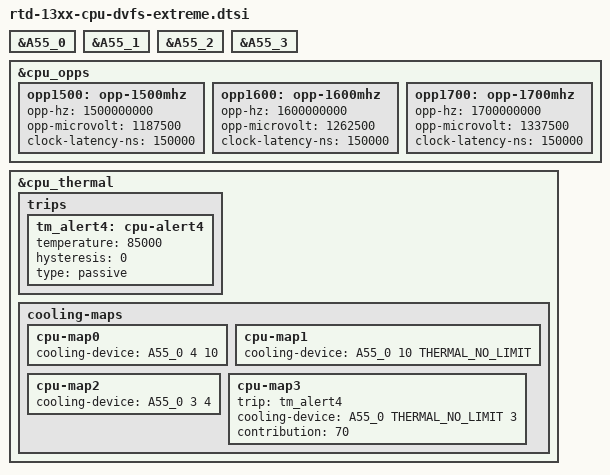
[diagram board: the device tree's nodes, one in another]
#include "rtd-13xx-cpu-dvfs.dtsi"

/*
 * Frequnecy overview
 *
 *    CDEV                             CDEV  CDEV  CDEV  CDEV
 *      ST  FREQUENCY   HLS   SUSPEND  MAP0  MAP1  MAP2  MAP3
 *       0       1700    V                                |
 *       1       1600    V                                |
 *       2       1500    V                                |
 *       3       1400    V                         -+-   -+-
 *       4       1300                  -+-         -+-
 *       5       1200            V      |
 *       6       1100                   |
 *       7       1000                   |
 *       8        900                   |
 *       9        800                  -+-
 *      10        700                        -+-
 *      11        600                         |
 *      12        500                         |
 *      13        400                         |
 *      14        300                         |
 */

&A55_0 {
};
&A55_1 {
};
&A55_2 {
};
&A55_3 {
};

&cpu_opps {
	opp1500: opp-1500mhz {
		opp-hz = /bits/ 64 <1500000000>;
		opp-microvolt = <1187500>;
		clock-latency-ns = <150000>;
		status = "okay";
	};
	opp1600: opp-1600mhz {
		opp-hz = /bits/ 64 <1600000000>;
		opp-microvolt = <1262500>;
		clock-latency-ns = <150000>;
		status = "okay";
	};
	opp1700: opp-1700mhz {
		opp-hz = /bits/ 64 <1700000000>;
		opp-microvolt = <1337500>;
		clock-latency-ns = <150000>;
		status = "okay";
	};
};
&cpu_thermal {
	trips {
		tm_alert4: cpu-alert4 {
			temperature = <85000>;
			hysteresis = <0>;
			type = "passive";
		};
	};
	cooling-maps {
		cpu-map0 {
			cooling-device = <&A55_0 4 10>;
		};
		cpu-map1 {
			cooling-device = <&A55_0 10 THERMAL_NO_LIMIT>;
		};
		cpu-map2 {
			cooling-device = <&A55_0 3 4>;
		};
		cpu-map3 {
			trip = <&tm_alert4>;
			cooling-device = <&A55_0 THERMAL_NO_LIMIT 3>;
			contribution = <70>;
		};
	};
};

